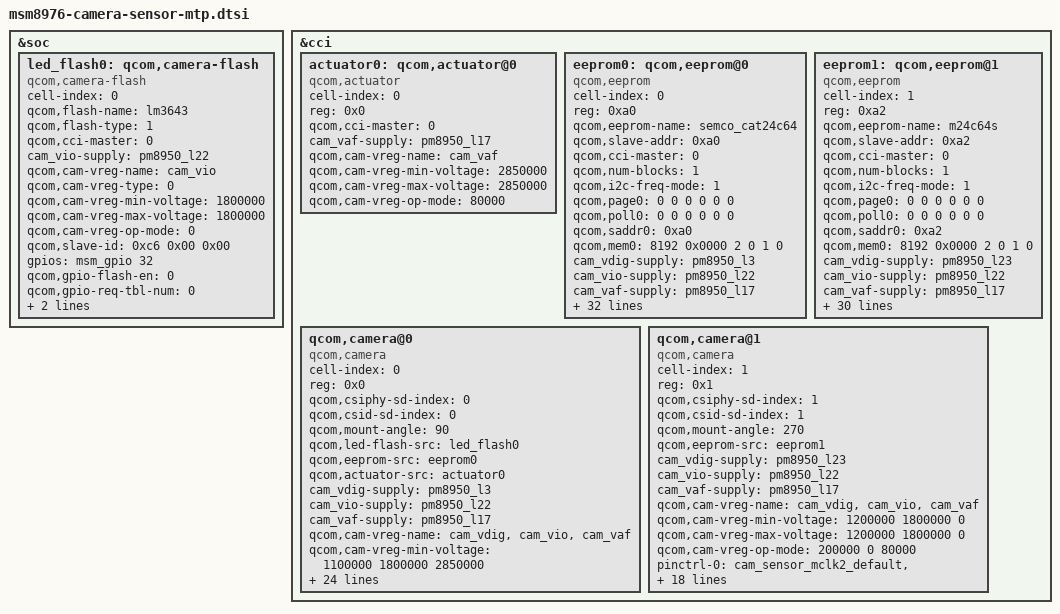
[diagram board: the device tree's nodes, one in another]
/*
 * Copyright (c) 2015-2016, The Linux Foundation. All rights reserved.
 *
 * This program is free software; you can redistribute it and/or modify
 * it under the terms of the GNU General Public License version 2 and
 * only version 2 as published by the Free Software Foundation.
 *
 * This program is distributed in the hope that it will be useful,
 * but WITHOUT ANY WARRANTY; without even the implied warranty of
 * MERCHANTABILITY or FITNESS FOR A PARTICULAR PURPOSE.  See the
 * GNU General Public License for more details.
 */

&soc {
	led_flash0: qcom,camera-flash {
		cell-index = <0>;
		compatible = "qcom,camera-flash";
		qcom,flash-name = "lm3643";
		qcom,flash-type = <1>;
		qcom,cci-master = <0>;
		cam_vio-supply = <&pm8950_l22>;
		qcom,cam-vreg-name = "cam_vio";
		qcom,cam-vreg-type = <0>;
		qcom,cam-vreg-min-voltage = <1800000>;
		qcom,cam-vreg-max-voltage = <1800000>;
		qcom,cam-vreg-op-mode = <0>;
		qcom,slave-id = <0xc6 0x00 0x00>;
		gpios = <&msm_gpio 32 0>;
		qcom,gpio-flash-en = <0>;
		qcom,gpio-req-tbl-num = <0>;
		qcom,gpio-req-tbl-flags = <0>;
		qcom,gpio-req-tbl-label = "FLASH_EN";
	};
};

&cci {
    actuator0: qcom,actuator@0 {
        cell-index = <0>;
        reg = <0x0>;
        compatible = "qcom,actuator";
        qcom,cci-master = <0>;
        cam_vaf-supply = <&pm8950_l17>;
        qcom,cam-vreg-name = "cam_vaf";
        qcom,cam-vreg-min-voltage = <2850000>;
        qcom,cam-vreg-max-voltage = <2850000>;
        qcom,cam-vreg-op-mode = <80000>;
    };

    eeprom0: qcom,eeprom@0 {
		cell-index = <0>;
		reg = <0xa0>;
		qcom,eeprom-name = "semco_cat24c64";
		compatible = "qcom,eeprom";
		qcom,slave-addr = <0xa0>;
		qcom,cci-master = <0>;
		qcom,num-blocks = <1>;
		qcom,i2c-freq-mode =<1>;

		qcom,page0 = <0 0 0 0 0 0>;
		qcom,poll0 = <0 0 0 0 0 0>;
		qcom,saddr0 = <0xa0>;
		qcom,mem0 = <8192 0x0000 2 0 1 0>;

        cam_vdig-supply = <&pm8950_l3>;
        cam_vio-supply = <&pm8950_l22>;
        cam_vaf-supply = <&pm8950_l17>;
		qcom,cam-vreg-name = "cam_vdig", "cam_vio", "cam_vaf";
		qcom,cam-vreg-min-voltage = <1100000 1800000 2850000>;
		qcom,cam-vreg-max-voltage = <1100000 1800000 2850000>;
		qcom,cam-vreg-op-mode = <105000 0 100000>;
		pinctrl-names = "cam_default", "cam_suspend";
		pinctrl-0 = <&cam_sensor_mclk2_default
				&cam_sensor_front1_default>;
		pinctrl-1 = <&cam_sensor_mclk2_sleep
                &cam_sensor_front1_sleep>;
		gpios = <&msm_gpio 26 0>,
			<&msm_gpio 129 0>,
			<&msm_gpio 35 0>,
			<&msm_gpio 34 0>;
        qcom,gpio-reset = <1>;
        qcom,gpio-standby = <2>;
        qcom,gpio-vana = <3>;
		qcom,gpio-req-tbl-num = <0 1 2 3>;
		qcom,gpio-req-tbl-flags = <1 0 0 0>;
		qcom,gpio-req-tbl-label = "CAMIF_MCLK0",
			"CAM_RESET",
			"CAM_STANDBY",
			"CAM_VANA";

		qcom,cam-power-seq-type = "sensor_vreg", "sensor_vreg", "sensor_vreg",
			"sensor_gpio", "sensor_gpio", "sensor_gpio", "sensor_clk";
		qcom,cam-power-seq-val = "cam_vdig", "cam_vaf", "cam_vio",
            "sensor_gpio_reset", "sensor_gpio_standby", "sensor_gpio_vana", "sensor_cam_mclk";
		qcom,cam-power-seq-cfg-val = <1 1 1 1 1 1 24000000>;
		qcom,cam-power-seq-delay = <1 1 1 30 30 5 5>;
		status = "ok";
		clocks = <&clock_gcc clk_mclk0_clk_src>,
			<&clock_gcc clk_gcc_camss_mclk0_clk>;
		clock-names = "cam_src_clk", "cam_clk";
		qcom,clock-rates = <24000000 0>;
	};

	eeprom1: qcom,eeprom@1 {
		cell-index = <1>;
		reg = <0xa2>;
		qcom,eeprom-name = "m24c64s";
		compatible = "qcom,eeprom";
		qcom,slave-addr = <0xa2>;
		qcom,cci-master = <0>;
		qcom,num-blocks = <1>;
		qcom,i2c-freq-mode =<1>;

		qcom,page0 = <0 0 0 0 0 0>;
		qcom,poll0 = <0 0 0 0 0 0>;
		qcom,saddr0 = <0xa2>;
		qcom,mem0 = <8192 0x0000 2 0 1 0>;

        cam_vdig-supply = <&pm8950_l23>;
        cam_vio-supply = <&pm8950_l22>;
        cam_vaf-supply = <&pm8950_l17>;
		qcom,cam-vreg-name = "cam_vdig", "cam_vio", "cam_vaf";
		qcom,cam-vreg-min-voltage = <1200000 1800000 0>;
		qcom,cam-vreg-max-voltage = <1200000 1800000 0>;
		qcom,cam-vreg-op-mode = <200000 0 80000>;
		pinctrl-names = "cam_default", "cam_suspend";
		pinctrl-0 = <&cam_sensor_mclk2_default
				&cam_sensor_front1_default>;
		pinctrl-1 = <&cam_sensor_mclk2_sleep
                &cam_sensor_front1_sleep>;
		gpios = <&msm_gpio 28 0>,
			<&msm_gpio 131 0>,
			<&msm_gpio 38 0>,
			<&msm_gpio 33 0>;
        qcom,gpio-reset = <1>;
        qcom,gpio-standby = <2>;
        qcom,gpio-vana = <3>;
		qcom,gpio-req-tbl-num = <0 1 2 3>;
		qcom,gpio-req-tbl-flags = <1 0 0 0>;
		qcom,gpio-req-tbl-label = "CAMIF_MCLK0",
			"CAM_RESET",
			"CAM_STANDBY",
			"CAM_VANA";

		qcom,cam-power-seq-type = "sensor_vreg", "sensor_vreg", "sensor_vreg",
			"sensor_gpio", "sensor_gpio", "sensor_gpio", "sensor_clk";
		qcom,cam-power-seq-val = "cam_vdig", "cam_vaf", "cam_vio",
            "sensor_gpio_reset", "sensor_gpio_standby", "sensor_gpio_vana", "sensor_cam_mclk";
		qcom,cam-power-seq-cfg-val = <1 1 1 1 1 1 24000000>;
		qcom,cam-power-seq-delay = <1 1 1 30 30 5 5>;
		status = "ok";
		clocks = <&clock_gcc clk_mclk2_clk_src>,
			<&clock_gcc clk_gcc_camss_mclk2_clk>;
		clock-names = "cam_src_clk", "cam_clk";
		qcom,clock-rates = <24000000 0>;
	};

    qcom,camera@0 {
		cell-index = <0>;
		compatible = "qcom,camera";
		reg = <0x0>;
		qcom,csiphy-sd-index = <0>;
		qcom,csid-sd-index = <0>;
		qcom,mount-angle = <90>;
		qcom,led-flash-src = <&led_flash0>;
		qcom,eeprom-src = <&eeprom0>;
		qcom,actuator-src = <&actuator0>;
        cam_vdig-supply = <&pm8950_l3>;
        cam_vio-supply = <&pm8950_l22>;
        cam_vaf-supply = <&pm8950_l17>;
		qcom,cam-vreg-name = "cam_vdig", "cam_vio", "cam_vaf";
		qcom,cam-vreg-min-voltage = <1100000 1800000 2850000>;
		qcom,cam-vreg-max-voltage = <1100000 1800000 2850000>;
		qcom,cam-vreg-op-mode = <200000 0 100000>;
		pinctrl-names = "cam_default", "cam_suspend";
		pinctrl-0 = <&cam_sensor_mclk0_default
				&cam_sensor_rear_default
				&cam_sensor_rear_vana>;
		pinctrl-1 = <&cam_sensor_mclk0_sleep &cam_sensor_rear_sleep
				&cam_sensor_rear_vana_sleep>;
		gpios = <&msm_gpio 26 0>,
			<&msm_gpio 129 0>,
            <&msm_gpio 35 0>,
            <&msm_gpio 34 0>;
		qcom,gpio-reset = <1>;
        qcom,gpio-standby = <2>;
        qcom,gpio-vana = <3>;
		qcom,gpio-req-tbl-num = <0 1 2 3>;
		qcom,gpio-req-tbl-flags = <1 0 0 0>;
		qcom,gpio-req-tbl-label = "CAMIF_MCLK0",
			"CAM_RESET0",
            "CAM_STANDBY0",
			"CAM_VANA";
		qcom,sensor-position = <0>;
		qcom,sensor-mode = <0>;
		qcom,cci-master = <0>;
		status = "ok";
		clocks = <&clock_gcc clk_mclk0_clk_src>,
				<&clock_gcc clk_gcc_camss_mclk0_clk>;
		clock-names = "cam_src_clk", "cam_clk";
		qcom,clock-rates = <24000000 0>;
	};

	qcom,camera@1 {
		cell-index = <1>;
		compatible = "qcom,camera";
		reg = <0x1>;
		qcom,csiphy-sd-index = <1>;
		qcom,csid-sd-index = <1>;
		qcom,mount-angle = <270>;
        qcom,eeprom-src = <&eeprom1>;
        cam_vdig-supply = <&pm8950_l23>;
        cam_vio-supply = <&pm8950_l22>;
        cam_vaf-supply = <&pm8950_l17>;
		qcom,cam-vreg-name = "cam_vdig", "cam_vio", "cam_vaf";
		qcom,cam-vreg-min-voltage = <1200000 1800000 0>;
		qcom,cam-vreg-max-voltage = <1200000 1800000 0>;
		qcom,cam-vreg-op-mode = <200000 0 80000>;
		pinctrl-names = "cam_default", "cam_suspend";
		pinctrl-0 = <&cam_sensor_mclk2_default
				&cam_sensor_front1_default>;
		pinctrl-1 = <&cam_sensor_mclk2_sleep
				&cam_sensor_front1_sleep>;
		gpios = <&msm_gpio 28 0>,
			<&msm_gpio 131 0>,
			<&msm_gpio 38 0>,
			<&msm_gpio 33 0>;
		qcom,gpio-reset = <1>;
		qcom,gpio-standby = <2>;
		qcom,gpio-vana = <3>;
		qcom,gpio-req-tbl-num = <0 1 2 3>;
		qcom,gpio-req-tbl-flags = <1 0 0 0>;
		qcom,gpio-req-tbl-label = "CAMIF_MCLK1",
			"CAM_RESET1",
			"CAM_STANDBY1",
			"CAM_VANA";
		qcom,sensor-position = <1>;
		qcom,sensor-mode = <0>;
		qcom,cci-master = <0>;
		status = "ok";
		clocks = <&clock_gcc clk_mclk2_clk_src>,
				<&clock_gcc clk_gcc_camss_mclk2_clk>;
		clock-names = "cam_src_clk", "cam_clk";
		qcom,clock-rates = <24000000 0>;
	};
};
